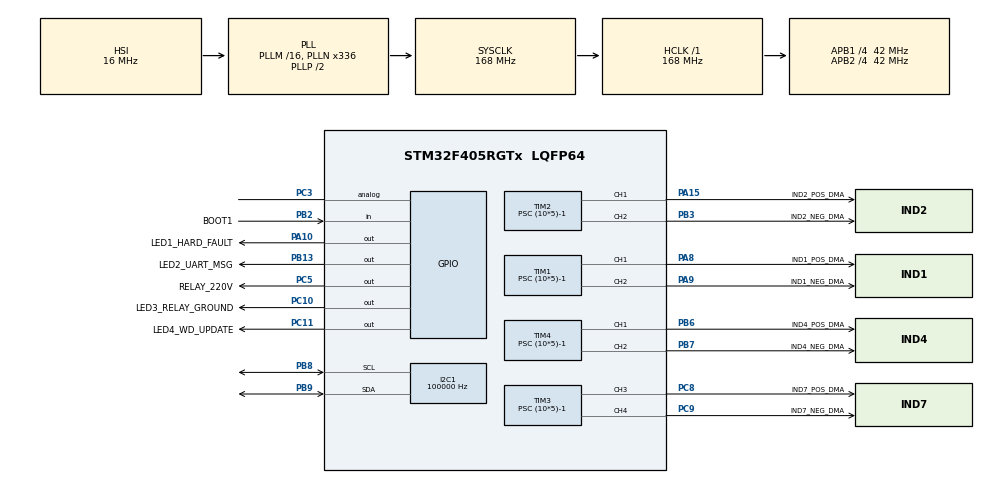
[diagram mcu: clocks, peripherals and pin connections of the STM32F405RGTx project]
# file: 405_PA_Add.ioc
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Dma.Request0=TIM1_CH1
Dma.Request1=TIM1_CH2
Dma.Request2=TIM2_CH1
Dma.Request3=TIM3_CH3
Dma.Request4=TIM4_CH1
Dma.Request5=TIM4_CH2
Dma.Request6=TIM2_CH2/CH4
Dma.Request7=TIM3_CH4/UP
Dma.TIM1_CH1.0.Direction=DMA_MEMORY_TO_PERIPH
Dma.TIM1_CH1.0.FIFOMode=DMA_FIFOMODE_DISABLE
Dma.TIM1_CH1.0.Instance=DMA2_Stream1
Dma.TIM1_CH1.0.MemDataAlignment=DMA_MDATAALIGN_WORD
Dma.TIM1_CH1.0.MemInc=DMA_MINC_ENABLE
Dma.TIM1_CH1.0.Mode=DMA_CIRCULAR
Dma.TIM1_CH1.0.PeriphDataAlignment=DMA_PDATAALIGN_WORD
Dma.TIM1_CH1.0.PeriphInc=DMA_PINC_DISABLE
Dma.TIM1_CH1.0.Priority=DMA_PRIORITY_LOW
Dma.TIM1_CH2.1.Direction=DMA_MEMORY_TO_PERIPH
Dma.TIM1_CH2.1.FIFOMode=DMA_FIFOMODE_DISABLE
Dma.TIM1_CH2.1.Instance=DMA2_Stream2
Dma.TIM1_CH2.1.MemDataAlignment=DMA_MDATAALIGN_WORD
Dma.TIM1_CH2.1.MemInc=DMA_MINC_ENABLE
Dma.TIM1_CH2.1.Mode=DMA_CIRCULAR
Dma.TIM1_CH2.1.PeriphDataAlignment=DMA_PDATAALIGN_WORD
Dma.TIM1_CH2.1.PeriphInc=DMA_PINC_DISABLE
Dma.TIM1_CH2.1.Priority=DMA_PRIORITY_LOW
Dma.TIM2_CH1.2.Direction=DMA_MEMORY_TO_PERIPH
Dma.TIM2_CH1.2.FIFOMode=DMA_FIFOMODE_DISABLE
Dma.TIM2_CH1.2.Instance=DMA1_Stream5
Dma.TIM2_CH1.2.MemDataAlignment=DMA_MDATAALIGN_WORD
Dma.TIM2_CH1.2.MemInc=DMA_MINC_ENABLE
Dma.TIM2_CH1.2.Mode=DMA_CIRCULAR
Dma.TIM2_CH1.2.PeriphDataAlignment=DMA_PDATAALIGN_WORD
Dma.TIM2_CH1.2.PeriphInc=DMA_PINC_DISABLE
Dma.TIM2_CH1.2.Priority=DMA_PRIORITY_LOW
Dma.TIM2_CH2/CH4.6.Direction=DMA_MEMORY_TO_PERIPH
Dma.TIM2_CH2/CH4.6.FIFOMode=DMA_FIFOMODE_DISABLE
Dma.TIM2_CH2/CH4.6.Instance=DMA1_Stream6
Dma.TIM2_CH2/CH4.6.MemDataAlignment=DMA_MDATAALIGN_WORD
Dma.TIM2_CH2/CH4.6.MemInc=DMA_MINC_ENABLE
Dma.TIM2_CH2/CH4.6.Mode=DMA_CIRCULAR
Dma.TIM2_CH2/CH4.6.PeriphDataAlignment=DMA_PDATAALIGN_WORD
Dma.TIM2_CH2/CH4.6.PeriphInc=DMA_PINC_DISABLE
Dma.TIM2_CH2/CH4.6.Priority=DMA_PRIORITY_LOW
Dma.TIM3_CH3.3.Direction=DMA_MEMORY_TO_PERIPH
Dma.TIM3_CH3.3.FIFOMode=DMA_FIFOMODE_DISABLE
Dma.TIM3_CH3.3.Instance=DMA1_Stream7
Dma.TIM3_CH3.3.MemDataAlignment=DMA_MDATAALIGN_WORD
Dma.TIM3_CH3.3.MemInc=DMA_MINC_ENABLE
Dma.TIM3_CH3.3.Mode=DMA_CIRCULAR
Dma.TIM3_CH3.3.PeriphDataAlignment=DMA_PDATAALIGN_WORD
Dma.TIM3_CH3.3.PeriphInc=DMA_PINC_DISABLE
Dma.TIM3_CH3.3.Priority=DMA_PRIORITY_LOW
Dma.TIM3_CH4/UP.7.Direction=DMA_MEMORY_TO_PERIPH
Dma.TIM3_CH4/UP.7.FIFOMode=DMA_FIFOMODE_DISABLE
Dma.TIM3_CH4/UP.7.Instance=DMA1_Stream2
Dma.TIM3_CH4/UP.7.MemDataAlignment=DMA_MDATAALIGN_WORD
Dma.TIM3_CH4/UP.7.MemInc=DMA_MINC_ENABLE
Dma.TIM3_CH4/UP.7.Mode=DMA_CIRCULAR
Dma.TIM3_CH4/UP.7.PeriphDataAlignment=DMA_PDATAALIGN_WORD
Dma.TIM3_CH4/UP.7.PeriphInc=DMA_PINC_DISABLE
Dma.TIM3_CH4/UP.7.Priority=DMA_PRIORITY_LOW
Dma.TIM4_CH1.4.Direction=DMA_MEMORY_TO_PERIPH
Dma.TIM4_CH1.4.FIFOMode=DMA_FIFOMODE_DISABLE
Dma.TIM4_CH1.4.Instance=DMA1_Stream0
Dma.TIM4_CH1.4.MemDataAlignment=DMA_MDATAALIGN_WORD
Dma.TIM4_CH1.4.MemInc=DMA_MINC_ENABLE
Dma.TIM4_CH1.4.Mode=DMA_CIRCULAR
Dma.TIM4_CH1.4.PeriphDataAlignment=DMA_PDATAALIGN_WORD
Dma.TIM4_CH1.4.PeriphInc=DMA_PINC_DISABLE
Dma.TIM4_CH1.4.Priority=DMA_PRIORITY_LOW
Dma.TIM4_CH2.5.Direction=DMA_MEMORY_TO_PERIPH
Dma.TIM4_CH2.5.FIFOMode=DMA_FIFOMODE_DISABLE
Dma.TIM4_CH2.5.Instance=DMA1_Stream3
Dma.TIM4_CH2.5.MemDataAlignment=DMA_MDATAALIGN_WORD
Dma.TIM4_CH2.5.MemInc=DMA_MINC_ENABLE
Dma.TIM4_CH2.5.Mode=DMA_CIRCULAR
Dma.TIM4_CH2.5.PeriphDataAlignment=DMA_PDATAALIGN_WORD
Dma.TIM4_CH2.5.PeriphInc=DMA_PINC_DISABLE
Dma.TIM4_CH2.5.Priority=DMA_PRIORITY_LOW
FREERTOS.Queues01=SignalGeneratorQueue,40,tdRpiMessage,0,Dynamic,NULL,NULL
FREERTOS.Tasks01=defaultTask,24,512,StartDefaultTask,As weak,NULL,Dynamic,NULL,NULL;ChngSignalParam,24,512,ChangeSignalParamsTask,As weak,NULL,Dynamic,NULL,NULL
FREERTOS.configENABLE_FPU=1
FREERTOS.configTOTAL_HEAP_SIZE=20000
I2C1.ClockSpeed=100000
I2C1.DualAddressMode=I2C_DUALADDRESS_DISABLE
I2C1.GeneralCallMode=I2C_GENERALCALL_DISABLE
I2C1.I2C_Mode=I2C_Standard
I2C1.NoStretchMode=I2C_NOSTRETCH_DISABLE
I2C1.OwnAddress=0x55
IWDG.Prescaler=IWDG_PRESCALER_32
IWDG.Reload=4000
Mcu.Family=STM32F4
Mcu.Name=STM32F405RGTx
Mcu.Package=LQFP64
NVIC.DMA1_Stream0_IRQn=true\:6\:0\:true\:false\:true\:true\:false\:true\:true
NVIC.DMA1_Stream2_IRQn=true\:6\:0\:true\:false\:true\:true\:false\:true\:true
NVIC.DMA1_Stream3_IRQn=true\:6\:0\:true\:false\:true\:true\:false\:true\:true
NVIC.DMA1_Stream5_IRQn=true\:6\:0\:true\:false\:true\:true\:false\:true\:true
NVIC.DMA1_Stream6_IRQn=true\:6\:0\:true\:false\:true\:true\:false\:true\:true
NVIC.DMA1_Stream7_IRQn=true\:6\:0\:true\:false\:true\:true\:false\:true\:true
NVIC.DMA2_Stream1_IRQn=true\:6\:0\:true\:false\:true\:true\:false\:true\:true
NVIC.DMA2_Stream2_IRQn=true\:6\:0\:true\:false\:true\:true\:false\:true\:true
NVIC.I2C1_ER_IRQn=true\:5\:0\:false\:false\:true\:true\:true\:true\:true
NVIC.I2C1_EV_IRQn=true\:5\:0\:false\:false\:true\:true\:true\:true\:true
NVIC.PriorityGroup=NVIC_PRIORITYGROUP_4
NVIC.TIM1_CC_IRQn=true\:6\:0\:true\:false\:true\:true\:true\:true\:true
NVIC.TIM1_UP_TIM10_IRQn=true\:6\:0\:true\:false\:true\:true\:true\:true\:true
NVIC.TIM2_IRQn=true\:6\:0\:true\:false\:true\:true\:true\:true\:true
NVIC.TIM3_IRQn=true\:6\:0\:true\:false\:true\:true\:true\:true\:true
NVIC.TIM4_IRQn=true\:6\:0\:true\:false\:true\:true\:true\:true\:true
NVIC.TIM6_DAC_IRQn=true\:0\:0\:true\:false\:true\:false\:false\:true\:true
NVIC.TIM8_BRK_TIM12_IRQn=true\:10\:0\:true\:false\:true\:true\:true\:true\:true
NVIC.TIM8_UP_TIM13_IRQn=true\:10\:0\:true\:false\:true\:true\:true\:true\:true
NVIC.TimeBase=TIM6_DAC_IRQn
NVIC.TimeBaseIP=TIM6
PA0-WKUP.GPIO_ModeDefaultPP=GPIO_MODE_AF_OD
PA0-WKUP.GPIO_PuPd=GPIO_PULLUP
PA0-WKUP.Signal=UART4_TX
PA1.GPIO_ModeDefaultPP=GPIO_MODE_AF_OD
PA1.GPIO_PuPd=GPIO_PULLUP
PA1.Signal=UART4_RX
PA10.GPIO_Label=LED1_HARD_FAULT
PA10.Signal=GPIO_Output
PA13.Mode=Serial_Wire
PA13.Signal=SYS_JTMS-SWDIO
PA14.Mode=Serial_Wire
PA14.Signal=SYS_JTCK-SWCLK
PA15.GPIO_Label=IND2_POS_DMA
PA15.GPIO_PuPd=GPIO_NOPULL
PA15.GPIO_Speed=GPIO_SPEED_FREQ_VERY_HIGH
PA15.Signal=S_TIM2_CH1_ETR
PA8.GPIO_Label=IND1_POS_DMA
PA8.GPIO_PuPd=GPIO_NOPULL
PA8.GPIO_Speed=GPIO_SPEED_FREQ_VERY_HIGH
PA8.Signal=S_TIM1_CH1
PA9.GPIO_Label=IND1_NEG_DMA
PA9.GPIO_PuPd=GPIO_NOPULL
PA9.GPIO_Speed=GPIO_SPEED_FREQ_VERY_HIGH
PA9.Signal=S_TIM1_CH2
PB13.GPIO_Label=LED2_UART_MSG
PB13.Signal=GPIO_Output
PB2.GPIO_Label=BOOT1
PB2.Signal=GPIO_Input
PB3.GPIO_Label=IND2_NEG_DMA
PB3.GPIO_PuPd=GPIO_NOPULL
PB3.GPIO_Speed=GPIO_SPEED_FREQ_VERY_HIGH
PB3.Signal=S_TIM2_CH2
PB6.GPIO_Label=IND4_POS_DMA
PB6.GPIO_PuPd=GPIO_NOPULL
PB6.GPIO_Speed=GPIO_SPEED_FREQ_VERY_HIGH
PB6.Signal=S_TIM4_CH1
PB7.GPIO_Label=IND4_NEG_DMA
PB7.GPIO_PuPd=GPIO_NOPULL
PB7.GPIO_Speed=GPIO_SPEED_FREQ_VERY_HIGH
PB7.Signal=S_TIM4_CH2
PB8.GPIO_Mode=GPIO_MODE_AF_OD
PB8.GPIO_Pu=GPIO_PULLUP
PB8.GPIO_Speed=GPIO_SPEED_FREQ_VERY_HIGH
PB8.Mode=I2C
PB8.Signal=I2C1_SCL
PB9.GPIO_Mode=GPIO_MODE_AF_OD
PB9.GPIO_Pu=GPIO_PULLUP
PB9.GPIO_Speed=GPIO_SPEED_FREQ_VERY_HIGH
PB9.Mode=I2C
PB9.Signal=I2C1_SDA
PC10.GPIO_Label=LED3_RELAY_GROUND
PC10.Signal=GPIO_Output
PC11.GPIO_Label=LED4_WD_UPDATE
PC11.Signal=GPIO_Output
PC3.Signal=GPIO_Analog
PC5.GPIO_Label=RELAY_220V
PC5.GPIO_ModeDefaultOutputPP=GPIO_MODE_OUTPUT_OD
PC5.GPIO_PuPd=GPIO_PULLUP
PC5.PinState=GPIO_PIN_SET
PC5.Signal=GPIO_Output
PC8.GPIO_Label=IND7_POS_DMA
PC8.GPIO_PuPd=GPIO_NOPULL
PC8.GPIO_Speed=GPIO_SPEED_FREQ_VERY_HIGH
PC8.Signal=S_TIM3_CH3
PC9.GPIO_Label=IND7_NEG_DMA
PC9.GPIO_PuPd=GPIO_NOPULL
PC9.GPIO_Speed=GPIO_SPEED_FREQ_VERY_HIGH
PC9.Signal=S_TIM3_CH4
PH0-OSC_IN.Mode=HSE-External-Oscillator
PH0-OSC_IN.Signal=RCC_OSC_IN
PH1-OSC_OUT.Mode=HSE-External-Oscillator
PH1-OSC_OUT.Signal=RCC_OSC_OUT
ProjectManager.HeapSize=0x2000
ProjectManager.StackSize=0x4000
ProjectManager.TargetToolchain=EWARM V8.50
RCC.48MHZClocksFreq_Value=84000000
RCC.AHBFreq_Value=168000000
RCC.APB1CLKDivider=RCC_HCLK_DIV4
RCC.APB1Freq_Value=42000000
RCC.APB1TimFreq_Value=84000000
RCC.APB2CLKDivider=RCC_HCLK_DIV4
RCC.APB2Freq_Value=42000000
RCC.APB2TimFreq_Value=84000000
RCC.CortexFreq_Value=168000000
RCC.HCLKFreq_Value=168000000
RCC.HSE_VALUE=16000000
RCC.HSI_VALUE=16000000
RCC.LSE_VALUE=32768
RCC.PLLN=336
RCC.SYSCLKFreq_VALUE=168000000
RCC.SYSCLKSource=RCC_SYSCLKSOURCE_PLLCLK
RCC.VCOOutputFreq_Value=336000000
SH.S_TIM1_CH1.0=TIM1_CH1,PWM Generation1 CH1
SH.S_TIM1_CH2.0=TIM1_CH2,PWM Generation2 CH2
SH.S_TIM2_CH1_ETR.0=TIM2_CH1,PWM Generation1 CH1
SH.S_TIM2_CH2.0=TIM2_CH2,PWM Generation2 CH2
SH.S_TIM3_CH3.0=TIM3_CH3,PWM Generation3 CH3
SH.S_TIM3_CH4.0=TIM3_CH4,PWM Generation4 CH4
SH.S_TIM4_CH1.0=TIM4_CH1,PWM Generation1 CH1
SH.S_TIM4_CH2.0=TIM4_CH2,PWM Generation2 CH2
TIM1.Channel-PWM\ Generation1\ CH1=TIM_CHANNEL_1
TIM1.Channel-PWM\ Generation2\ CH2=TIM_CHANNEL_2
TIM1.OCFastMode_PWM-PWM\ Generation1\ CH1=TIM_OCFAST_ENABLE
TIM1.OCFastMode_PWM-PWM\ Generation2\ CH2=TIM_OCFAST_ENABLE
TIM1.OCIdleState_1=TIM_OCIDLESTATE_SET
TIM1.OCIdleState_2=TIM_OCIDLESTATE_SET
TIM1.OCPolarity_1=TIM_OCPOLARITY_LOW
TIM1.OCPolarity_2=TIM_OCPOLARITY_LOW
TIM1.Period=84-1
TIM1.Prescaler=(10*5)-1
TIM12.Period=(84000000/16/1000)-1
TIM2.Channel-PWM\ Generation1\ CH1=TIM_CHANNEL_1
TIM2.Channel-PWM\ Generation2\ CH2=TIM_CHANNEL_2
TIM2.OCFastMode_PWM-PWM\ Generation1\ CH1=TIM_OCFAST_ENABLE
TIM2.OCFastMode_PWM-PWM\ Generation2\ CH2=TIM_OCFAST_ENABLE
TIM2.OCPolarity_1=TIM_OCPOLARITY_LOW
TIM2.OCPolarity_2=TIM_OCPOLARITY_LOW
TIM2.Period=84-1
TIM2.Prescaler=(10*5)-1
TIM3.Channel-PWM\ Generation3\ CH3=TIM_CHANNEL_3
TIM3.Channel-PWM\ Generation4\ CH4=TIM_CHANNEL_4
TIM3.OCFastMode_PWM-PWM\ Generation3\ CH3=TIM_OCFAST_ENABLE
TIM3.OCFastMode_PWM-PWM\ Generation4\ CH4=TIM_OCFAST_ENABLE
TIM3.OCPolarity_3=TIM_OCPOLARITY_LOW
TIM3.OCPolarity_4=TIM_OCPOLARITY_LOW
TIM3.Period=84-1
TIM3.Prescaler=(10*5)-1
TIM4.Channel-PWM\ Generation1\ CH1=TIM_CHANNEL_1
TIM4.Channel-PWM\ Generation2\ CH2=TIM_CHANNEL_2
TIM4.OCFastMode_PWM-PWM\ Generation1\ CH1=TIM_OCFAST_ENABLE
TIM4.OCFastMode_PWM-PWM\ Generation2\ CH2=TIM_OCFAST_ENABLE
TIM4.OCPolarity_1=TIM_OCPOLARITY_LOW
TIM4.OCPolarity_2=TIM_OCPOLARITY_LOW
TIM4.Period=84-1
TIM4.Prescaler=(10*5)-1
VP_CRC_VS_CRC.Mode=CRC_Activate
VP_FREERTOS_VS_CMSIS_V2.Mode=CMSIS_V2
VP_IWDG_VS_IWDG.Mode=IWDG_Activate
VP_SYS_VS_tim6.Mode=TIM6
VP_TIM12_VS_ClockSourceINT.Mode=Internal
VP_TIM1_VS_ClockSourceINT.Mode=Internal
VP_TIM2_VS_ClockSourceINT.Mode=Internal
VP_TIM3_VS_ClockSourceINT.Mode=Internal
VP_TIM4_VS_ClockSourceINT.Mode=Internal
VP_TIM8_VS_ClockSourceINT.Mode=Internal
board=custom

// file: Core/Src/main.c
/* USER CODE BEGIN Header */
/**
  ******************************************************************************
  * @file           : main.c
  * @brief          : Main program body
  ******************************************************************************
  * @attention
  *
  * <h2><center>&copy; Copyright (c) 2022 STMicroelectronics.
  * All rights reserved.</center></h2>
  *
  * This software component is licensed by ST under Ultimate Liberty license
  * SLA0044, the "License"; You may not use this file except in compliance with
  * the License. You may obtain a copy of the License at:
  *                             www.st.com/SLA0044
  *
  ******************************************************************************
  */
/* USER CODE END Header */
#include "main.h"
#include "cmsis_os.h"
#include "crc.h"
#include "dma.h"
#include "i2c.h"
#include "iwdg.h"
#include "tim.h"
#include "gpio.h"

/* USER CODE BEGIN Includes */
#include "app/com_interface/com_interface_i2c.h"
/* USER CODE END Includes */

void SystemClock_Config(void);
void MX_FREERTOS_Init(void);

int main(void)
{

  /* MCU Configuration--------------------------------------------------------*/

  /* Reset of all peripherals, Initializes the Flash interface and the Systick. */
  HAL_Init();

  /* Configure the system clock */
  SystemClock_Config();

  /* Initialize all configured peripherals */
  MX_GPIO_Init();
  MX_DMA_Init();
  MX_TIM1_Init();
  MX_TIM2_Init();
  MX_TIM3_Init();
  MX_TIM4_Init();
  MX_TIM8_Init();
  MX_TIM12_Init();
  MX_CRC_Init();
  MX_IWDG_Init();
  MX_I2C1_Init();

  /* Init scheduler */
  osKernelInitialize();  /* Call init function for freertos objects (in freertos.c) */
  MX_FREERTOS_Init();

  /* Start scheduler */
  osKernelStart();

  /* We should never get here as control is now taken by the scheduler */
  /* Infinite loop */
  while (1)
  {

  }
}

void SystemClock_Config(void)
{
  RCC_OscInitTypeDef RCC_OscInitStruct = {0};
  RCC_ClkInitTypeDef RCC_ClkInitStruct = {0};

  /** Configure the main internal regulator output voltage
  */
  __HAL_RCC_PWR_CLK_ENABLE();
  __HAL_PWR_VOLTAGESCALING_CONFIG(PWR_REGULATOR_VOLTAGE_SCALE1);

  /** Initializes the RCC Oscillators according to the specified parameters
  * in the RCC_OscInitTypeDef structure.
  */
  RCC_OscInitStruct.OscillatorType = RCC_OSCILLATORTYPE_HSI|RCC_OSCILLATORTYPE_LSI;
  RCC_OscInitStruct.HSIState = RCC_HSI_ON;
  RCC_OscInitStruct.HSICalibrationValue = RCC_HSICALIBRATION_DEFAULT;
  RCC_OscInitStruct.LSIState = RCC_LSI_ON;
  RCC_OscInitStruct.PLL.PLLState = RCC_PLL_ON;
  RCC_OscInitStruct.PLL.PLLSource = RCC_PLLSOURCE_HSI;
  RCC_OscInitStruct.PLL.PLLM = 16;
  RCC_OscInitStruct.PLL.PLLN = 336;
  RCC_OscInitStruct.PLL.PLLP = RCC_PLLP_DIV2;
  RCC_OscInitStruct.PLL.PLLQ = 4;
  if (HAL_RCC_OscConfig(&RCC_OscInitStruct) != HAL_OK)
  {
    Error_Handler();
  }

  /** Initializes the CPU, AHB and APB buses clocks
  */
  RCC_ClkInitStruct.ClockType = RCC_CLOCKTYPE_HCLK|RCC_CLOCKTYPE_SYSCLK
                              |RCC_CLOCKTYPE_PCLK1|RCC_CLOCKTYPE_PCLK2;
  RCC_ClkInitStruct.SYSCLKSource = RCC_SYSCLKSOURCE_PLLCLK;
  RCC_ClkInitStruct.AHBCLKDivider = RCC_SYSCLK_DIV1;
  RCC_ClkInitStruct.APB1CLKDivider = RCC_HCLK_DIV4;
  RCC_ClkInitStruct.APB2CLKDivider = RCC_HCLK_DIV4;

  if (HAL_RCC_ClockConfig(&RCC_ClkInitStruct, FLASH_LATENCY_5) != HAL_OK)
  {
    Error_Handler();
  }
}

void HAL_TIM_PeriodElapsedCallback(TIM_HandleTypeDef *htim)
{
  if (htim->Instance == TIM6) {
    HAL_IncTick();
  }
}

void Error_Handler(void)
{
  /* USER CODE BEGIN Error_Handler_Debug */
  /* User can add his own implementation to report the HAL error return state */
  __disable_irq();
  LED_ON(LED1_HARD_FAULT_GPIO_Port, LED1_HARD_FAULT_Pin);
  LED_OFF(LED2_UART_MSG_GPIO_Port, LED2_UART_MSG_Pin);
  LED_OFF(LED4_WD_UPDATE_GPIO_Port, LED4_WD_UPDATE_Pin);
  while (1)
  {
  }
  /* USER CODE END Error_Handler_Debug */
}

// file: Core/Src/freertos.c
/* USER CODE BEGIN Header */
/**
  ******************************************************************************
  * File Name          : freertos.c
  * Description        : Code for freertos applications
  ******************************************************************************
  * @attention
  *
  * <h2><center>&copy; Copyright (c) 2023 STMicroelectronics.
  * All rights reserved.</center></h2>
  *
  * This software component is licensed by ST under Ultimate Liberty license
  * SLA0044, the "License"; You may not use this file except in compliance with
  * the License. You may obtain a copy of the License at:
  *                             www.st.com/SLA0044
  *
  ******************************************************************************
  */
/* USER CODE END Header */

#include "FreeRTOS.h"
#include "task.h"
#include "main.h"
#include "cmsis_os.h"

/* USER CODE BEGIN Includes */
#include "app/pwm_types.h"
/* USER CODE END Includes */

/* Definitions for defaultTask */
osThreadId_t defaultTaskHandle;
const osThreadAttr_t defaultTask_attributes = {
  .name = "defaultTask",
  .stack_size = 512 * 4,
  .priority = (osPriority_t) osPriorityNormal,
};
/* Definitions for ChngSignalParam */
osThreadId_t ChngSignalParamHandle;
const osThreadAttr_t ChngSignalParam_attributes = {
  .name = "ChngSignalParam",
  .stack_size = 512 * 4,
  .priority = (osPriority_t) osPriorityNormal,
};
/* Definitions for SignalGeneratorQueue */
osMessageQueueId_t SignalGeneratorQueueHandle;
const osMessageQueueAttr_t SignalGeneratorQueue_attributes = {
  .name = "SignalGeneratorQueue"
};

void StartDefaultTask(void *argument);
void ChangeSignalParamsTask(void *argument);

void MX_FREERTOS_Init(void); /* (MISRA C 2004 rule 8.1) */

void MX_FREERTOS_Init(void) {

  /* Create the queue(s) */
  /* creation of SignalGeneratorQueue */
  SignalGeneratorQueueHandle = osMessageQueueNew (80, sizeof(tdPwmData), &SignalGeneratorQueue_attributes);

  /* Create the thread(s) */
  /* creation of defaultTask */
  defaultTaskHandle = osThreadNew(StartDefaultTask, NULL, &defaultTask_attributes);

  /* creation of ChngSignalParam */
  ChngSignalParamHandle = osThreadNew(ChangeSignalParamsTask, NULL, &ChngSignalParam_attributes);

}

__weak void StartDefaultTask(void *argument)
{
  for(;;)
  {
    osDelay(1);
  }
}

__weak void ChangeSignalParamsTask(void *argument)
{
  for(;;)
  {
    osDelay(1);
  }
}
